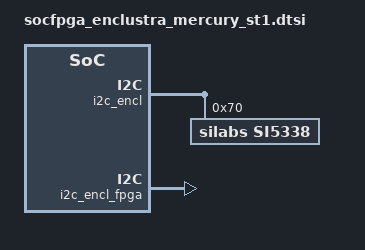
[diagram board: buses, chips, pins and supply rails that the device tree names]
// SPDX-License-Identifier: GPL-2.0+ OR MIT
/*
 * Copyright (C) 2024 Enclustra GmbH - https://www.enclustra.com
 */

&i2c_encl {
	si5338: clock-controller@70 {
		compatible = "silabs,si5338";
		reg = <0x70>;
	};
};

&i2c_encl_fpga {
	status = "okay";
};
